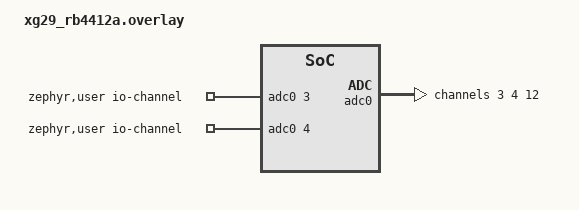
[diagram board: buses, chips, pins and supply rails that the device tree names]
/*
 * SPDX-License-Identifier: Apache-2.0
 *
 * Copyright (c) 2025 Silicon Laboratories Inc.
 */

#include <dt-bindings/pinctrl/silabs/xg29-pinctrl.h>
#include <dt-bindings/adc/silabs-adc.h>

/ {
	zephyr,user {
		io-channels = <&adc0 3>, <&adc0 4>;
	};
};

&pinctrl {
	adc0_default: adc0_default {
		group0 {
			/* Allocate odd Analog bus 0 on GPIO port C/D to IADC
			 * for access to pin PD3 and PC3.
			 * Allocate even Analog bus 0 on GPIO port A to IADC
			 * for access to pin PA8.
			 */
			silabs,analog-bus = <ABUS_CDODD0_IADC0>, <ABUS_AEVEN0_IADC0>;
		};
	};
};

&adc0 {
	pinctrl-0 = <&adc0_default>;
	pinctrl-names = "default";
	#address-cells = <1>;
	#size-cells = <0>;
	status = "okay";

	channel@3 {
		reg = <3>;
		zephyr,gain = "ADC_GAIN_1";
		zephyr,reference = "ADC_REF_INTERNAL";
		zephyr,acquisition-time = <ADC_ACQ_TIME_DEFAULT>;
		zephyr,oversampling = <5>;
		zephyr,resolution = <16>;
		zephyr,input-positive = <IADC_INPUT_AVDD>;
	};

	channel@4 {
		reg = <4>;
		zephyr,gain = "ADC_GAIN_1";
		zephyr,reference = "ADC_REF_VDD_1";
		zephyr,vref-mv = <3300>;
		zephyr,acquisition-time = <ADC_ACQ_TIME_DEFAULT>;
		zephyr,oversampling = <5>;
		zephyr,resolution = <12>;
		zephyr,input-positive = <IADC_INPUT_PD3>;
	};

	channel@c {
		reg = <12>;
		zephyr,gain = "ADC_GAIN_1";
		zephyr,reference = "ADC_REF_VDD_1";
		zephyr,vref-mv = <3300>;
		zephyr,acquisition-time = <ADC_ACQ_TIME_DEFAULT>;
		zephyr,oversampling = <5>;
		zephyr,resolution = <16>;
		zephyr,input-positive = <IADC_INPUT_PC3>; /* WPK EXP HEADER 10 */
		zephyr,input-negative = <IADC_INPUT_PA8>; /* WPK EXP HEADER 13 */
	};
};
